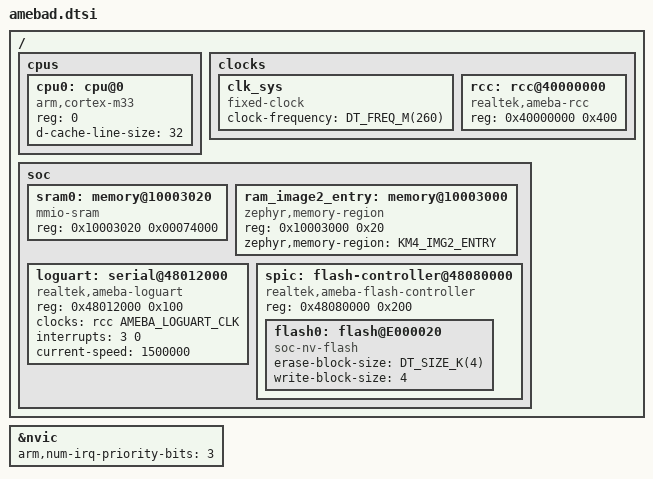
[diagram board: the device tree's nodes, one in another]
/*
 * Copyright (c) 2024 Realtek Semiconductor Corp.
 *
 * SPDX-License-Identifier: Apache-2.0
 */

#include <mem.h>
#include <freq.h>
#include <arm/armv8-m.dtsi>

#define AMEBA_LOGUART_CLK 13 /* loguart clk idx */
// #include <zephyr/dt-bindings/clock/amebadplus_clock.h>
// #include <zephyr/dt-bindings/dma/ameba_dma.h>
// #include <zephyr/dt-bindings/led/led.h>
// #include <zephyr/dt-bindings/adc/adc.h>
// #include <zephyr/dt-bindings/i2c/i2c.h>
// #include <zephyr/dt-bindings/gpio/gpio.h>
// #include <zephyr/dt-bindings/pwm/pwm.h>
// #include <zephyr/dt-bindings/usb/ameba_usb_ep.h>
// #include <zephyr/dt-bindings/input/input-event-codes.h>

/ {
	cpus {
		#address-cells = <1>;
		#size-cells = <0>;

		cpu0: cpu@0 {
			device_type = "cpu";
			compatible = "arm,cortex-m33";
			reg = <0>;
			d-cache-line-size = <32>;
			#address-cells = <1>;
			#size-cells = <1>;
		};
	};

	clocks {
		#address-cells = <1>;
		#size-cells = <1>;

		clk_sys: clk_sys {
			#clock-cells = <0>;
			compatible = "fixed-clock";
			clock-frequency = <DT_FREQ_M(260)>;
		};

		rcc: rcc@40000000 {
			compatible = "realtek,ameba-rcc";
			#clock-cells = <1>;
			reg = <0x40000000 0x400>;
		};
	};

	soc {
		sram0: memory@10003020 {
			compatible = "mmio-sram";
			reg = <0x10003020 0x00074000>;
		};

		ram_image2_entry: memory@10003000 {
			compatible = "zephyr,memory-region";
			reg = <0x10003000 0x20>;
			zephyr,memory-region = "KM4_IMG2_ENTRY";
		};

		loguart: serial@48012000 {
			compatible = "realtek,ameba-loguart";
			reg = <0x48012000 0x100>;
			clocks = <&rcc AMEBA_LOGUART_CLK>;
			interrupts = <3 0>;
			current-speed = <1500000>;
		};

		spic: flash-controller@48080000 {
			compatible = "realtek,ameba-flash-controller";
			reg = <0x48080000 0x200>;
			/* interrupts = <51 0>; */

			#address-cells = <1>;
			#size-cells = <1>;

			flash0: flash@E000020 {
				compatible = "soc-nv-flash";
				erase-block-size = <DT_SIZE_K(4)>;
				write-block-size = <4>;
				/* Flash size is specified in board dts */
			};
		};
	};
};

&nvic {
	arm,num-irq-priority-bits = <3>;
};
